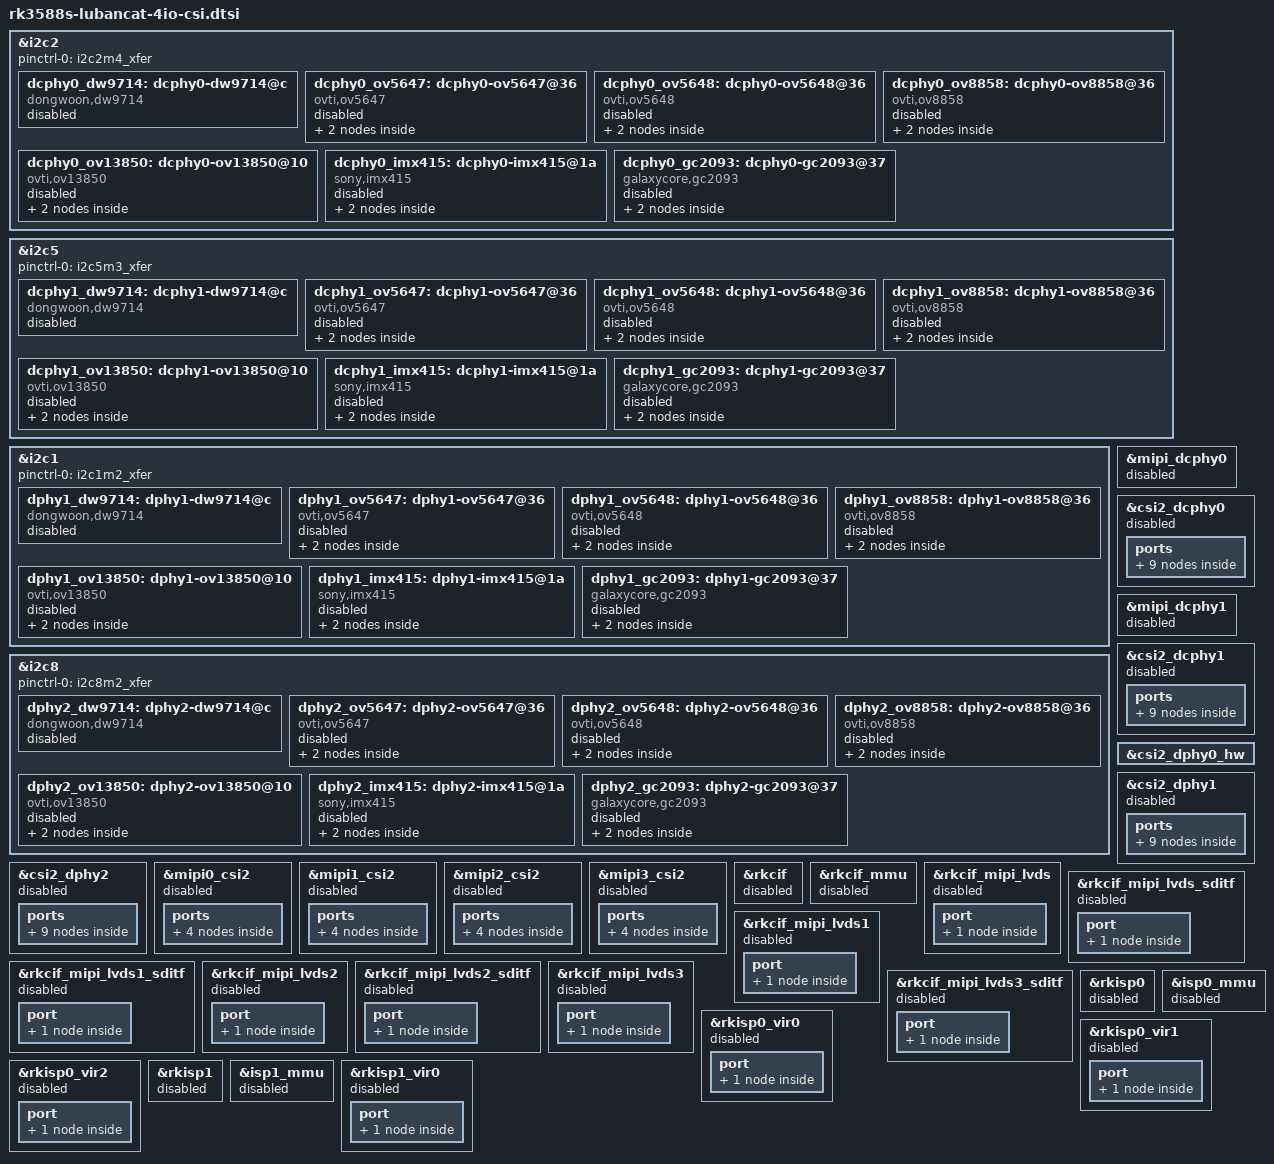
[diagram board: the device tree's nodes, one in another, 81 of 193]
// SPDX-License-Identifier: (GPL-2.0+ OR MIT)
/*
 * Copyright (c) 2020 Rockchip Electronics Co., Ltd.
 *
 */

#include "rk3588-lubancat-cam.dtsi"

/* CAM0 */
&i2c2 {
	status = "okay";
	pinctrl-names = "default";
	pinctrl-0 = <&i2c2m4_xfer>;

	dcphy0_dw9714: dcphy0-dw9714@c {
		status = "disabled";
		compatible = "dongwoon,dw9714";
		reg = <0xc>;
		rockchip,camera-module-index = <0>;
		rockchip,vcm-max-current = <100>;
		rockchip,vcm-start-current = <0>;
		rockchip,vcm-rated-current = <100>;
		rockchip,vcm-step-mode = <0xd>;
		rockchip,vcm-dlc-enable = <0>;
		rockchip,vcm-mclk = <0>;
		rockchip,vcm-t-src = <0>;
		rockchip,camera-module-facing = "back";
	};

	dcphy0_ov5647: dcphy0-ov5647@36 {
		compatible = "ovti,ov5647";
		status = "disabled";
		reg = <0x36>;
		clocks = <&ext_cam_25m_clk>;
		clock-names = "ext_cam_25m_clk";
		pwdn-gpios = <&gpio4 RK_PA6 GPIO_ACTIVE_LOW>;
		lens-focus = <&dcphy0_dw9714>;

		port {
			ov5647_dcphy0_out: endpoint {
				remote-endpoint = <&dcphy0_in_ov5647>;
				data-lanes = <1 2>;
			};
		};
	};

	dcphy0_ov5648: dcphy0-ov5648@36 {
		compatible = "ovti,ov5648";
		status = "disabled";
		reg = <0x36>;
		clocks = <&ext_cam_24m_clk>;
		clock-names = "xvclk";
		dovdd-supply= <&cam_dovdd>; /* 1.8v */
		avdd-supply = <&cam_avdd>;  /* 2.8v */
		dvdd-supply = <&cam_dvdd>;  /* 1.2v */
		pwdn-gpios = <&gpio4 RK_PA6 GPIO_ACTIVE_HIGH>;
		reset-gpios = <&gpio4 RK_PA7 GPIO_ACTIVE_LOW>;
		rotation = <180>;

		rockchip,camera-module-index = <0>;
		rockchip,camera-module-facing = "back";
		rockchip,camera-module-name = "THDS11073";
		rockchip,camera-module-lens-name = "Largan-40122a1";
		lens-focus = <&dcphy0_dw9714>;

		port {
			/* MIPI CSI-2 bus endpoint */
			ov5648_dcphy0_out: endpoint {
				remote-endpoint = <&dcphy0_in_ov5648>;
				clock-lanes = <0>;
				data-lanes = <1 2>;
			};
		};
	};

	dcphy0_ov8858: dcphy0-ov8858@36 {
		compatible = "ovti,ov8858";
		status = "disabled";
		reg = <0x36>;
		clocks = <&ext_cam_24m_clk>;
		clock-names = "xvclk";
		dovdd-supply= <&cam_dovdd>; /* 1.8v */
		avdd-supply = <&cam_avdd>;  /* 2.8v */
		dvdd-supply = <&cam_dvdd>;  /* 1.2v */
		pwdn-gpios = <&gpio4 RK_PA6 GPIO_ACTIVE_HIGH>;
		reset-gpios = <&gpio4 RK_PA7 GPIO_ACTIVE_HIGH>;
		rotation = <180>;

		rockchip,camera-module-index = <0>;
		rockchip,camera-module-facing = "back";
		rockchip,camera-module-name = "HS5885-BNSM1018-V01";
		rockchip,camera-module-lens-name = "default";
		lens-focus = <&dcphy0_dw9714>;

		port {
			/* MIPI CSI-2 bus endpoint */
			ov8858_dcphy0_out: endpoint {
				remote-endpoint = <&dcphy0_in_ov8858>;
				clock-lanes = <0>;
				data-lanes = <1 2>;
			};
		};
	};

   	dcphy0_ov13850: dcphy0-ov13850@10 {
		compatible = "ovti,ov13850";
		status = "disabled";
		reg = <0x10>;
		clocks = <&ext_cam_24m_clk>;
		clock-names = "xvclk";
		dovdd-supply= <&cam_dovdd>; /* 1.8v */
		avdd-supply = <&cam_avdd>;  /* 2.8v */
		dvdd-supply = <&cam_dvdd>;  /* 1.2v */
		pwdn-gpios = <&gpio4 RK_PA6 GPIO_ACTIVE_HIGH>;
		reset-gpios = <&gpio4 RK_PA7 GPIO_ACTIVE_HIGH>;
		rotation = <180>;

		rockchip,camera-module-index = <2>;
		rockchip,camera-module-facing = "back";
		rockchip,camera-module-name = "ZC-OV13850R2A-V1";
		rockchip,camera-module-lens-name = "Largan-50064B31";
		lens-focus = <&dcphy0_dw9714>;

		port {
			/* MIPI CSI-2 bus endpoint */
			ov13850_dcphy0_out: endpoint {
				remote-endpoint = <&dcphy0_in_ov13850>;
				clock-lanes = <0>;
				data-lanes = <1 2>;
			};
		};
	};

	dcphy0_imx415: dcphy0-imx415@1a {
		compatible = "sony,imx415";
		status = "disabled";
		reg = <0x1a>;
		clocks = <&ext_cam_37m_clk>;
		clock-names = "xvclk";
		power-domains = <&power RK3588_PD_VI>;
		avdd-supply = <&cam_avdd>;
		dovdd-supply = <&cam_dovdd>;
		dvdd-supply = <&cam_dvdd>;
		pwdn-gpios = <&gpio4 RK_PA6 GPIO_ACTIVE_HIGH>;
		reset-gpios = <&gpio4 RK_PA7 GPIO_ACTIVE_LOW>;

		rockchip,camera-module-index = <0>;
		rockchip,camera-module-facing = "back";
		rockchip,camera-module-name = "CMK-OT2022-PX1";
		rockchip,camera-module-lens-name = "IR0147-50IRC-8M-F20";
		// NO_HDR:0 HDR_X2:5 HDR_X3:6
		// rockchip,camera-hdr-mode = <0>;
		port {
			imx415_dcphy0_out: endpoint {
				remote-endpoint = <&dcphy0_in_imx415>;
				data-lanes = <1 2 3 4>;
			};
		};
	};

	dcphy0_gc2093: dcphy0-gc2093@37 {
		compatible = "galaxycore,gc2093";
		status = "disabled";
		reg = <0x37>;
		clocks = <&ext_cam_24m_clk>;
		clock-names = "xvclk";
		//power-domains = <&power RK3588_PD_VI>;

		avdd-supply = <&cam_avdd>;
		dovdd-supply = <&cam_dovdd>;
		dvdd-supply = <&cam_dvdd>;
		pwdn-gpios = <&gpio4 RK_PA6 GPIO_ACTIVE_HIGH>;
		reset-gpios = <&gpio4 RK_PA7 GPIO_ACTIVE_LOW>;

		rockchip,camera-module-index = <0>;
		rockchip,camera-module-facing = "front";
		rockchip,camera-module-name = "SIDA209300461";
		rockchip,camera-module-lens-name = "60IRC-F20";

		// NO_HDR:0 HDR_X2:5 HDR_X3:6
		// rockchip,camera-hdr-mode = <0>;
		port {
			gc2093_dcphy0_out: endpoint {
				remote-endpoint = <&dcphy0_in_gc2093>;
				data-lanes = <1 2 3 4>;
			};
		};
	};
};

/* CAM1 */
&i2c5 {
	status = "okay";
	pinctrl-names = "default";
	pinctrl-0 = <&i2c5m3_xfer>;

	dcphy1_dw9714: dcphy1-dw9714@c {
		status = "disabled";
		compatible = "dongwoon,dw9714";
		reg = <0xc>;
		rockchip,camera-module-index = <1>;
		rockchip,vcm-max-current = <100>;
		rockchip,vcm-start-current = <0>;
		rockchip,vcm-rated-current = <100>;
		rockchip,vcm-step-mode = <0xd>;
		rockchip,vcm-dlc-enable = <0>;
		rockchip,vcm-mclk = <0>;
		rockchip,vcm-t-src = <0>;
		rockchip,camera-module-facing = "back";
	};

	dcphy1_ov5647: dcphy1-ov5647@36 {
		compatible = "ovti,ov5647";
		status = "disabled";
		reg = <0x36>;
		clocks = <&ext_cam_25m_clk>;
		clock-names = "ext_cam_25m_clk";
		pwdn-gpios = <&gpio4 RK_PB0 GPIO_ACTIVE_LOW>;
		lens-focus = <&dcphy1_dw9714>;

		port {
			ov5647_dcphy1_out: endpoint {
				remote-endpoint = <&dcphy1_in_ov5647>;
				data-lanes = <1 2>;
			};
		};
	};

	dcphy1_ov5648: dcphy1-ov5648@36 {
		compatible = "ovti,ov5648";
		status = "disabled";
		reg = <0x36>;
		clocks = <&ext_cam_24m_clk>;
		clock-names = "xvclk";
		dovdd-supply= <&cam_dovdd>; /* 1.8v */
		avdd-supply = <&cam_avdd>;  /* 2.8v */
		dvdd-supply = <&cam_dvdd>;  /* 1.2v */
		pwdn-gpios = <&gpio4 RK_PB0 GPIO_ACTIVE_HIGH>;
		reset-gpios = <&gpio4 RK_PA0 GPIO_ACTIVE_LOW>;
		rotation = <180>;

		rockchip,camera-module-index = <1>;
		rockchip,camera-module-facing = "back";
		rockchip,camera-module-name = "THDS11073";
		rockchip,camera-module-lens-name = "Largan-40122a1";
		lens-focus = <&dcphy1_dw9714>;

		port {
			/* MIPI CSI-2 bus endpoint */
			ov5648_dcphy1_out: endpoint {
				remote-endpoint = <&dcphy1_in_ov5648>;
				clock-lanes = <0>;
				data-lanes = <1 2>;
			};
		};
	};

	dcphy1_ov8858: dcphy1-ov8858@36 {
		compatible = "ovti,ov8858";
		status = "disabled";
		reg = <0x36>;
		clocks = <&ext_cam_24m_clk>;
		clock-names = "xvclk";
		dovdd-supply= <&cam_dovdd>; /* 1.8v */
		avdd-supply = <&cam_avdd>;  /* 2.8v */
		dvdd-supply = <&cam_dvdd>;  /* 1.2v */
		pwdn-gpios = <&gpio4 RK_PB0 GPIO_ACTIVE_HIGH>;
		reset-gpios = <&gpio4 RK_PA0 GPIO_ACTIVE_HIGH>;
		rotation = <180>;

		rockchip,camera-module-index = <1>;
		rockchip,camera-module-facing = "back";
		rockchip,camera-module-name = "HS5885-BNSM1018-V01";
		rockchip,camera-module-lens-name = "default";
		lens-focus = <&dcphy1_dw9714>;

		port {
			/* MIPI CSI-2 bus endpoint */
			ov8858_dcphy1_out: endpoint {
				remote-endpoint = <&dcphy1_in_ov8858>;
				clock-lanes = <0>;
				data-lanes = <1 2>;
			};
		};
	};

   dcphy1_ov13850: dcphy1-ov13850@10 {
		compatible = "ovti,ov13850";
		status = "disabled";
		reg = <0x10>;
		clocks = <&ext_cam_24m_clk>;
		clock-names = "xvclk";
		dovdd-supply= <&cam_dovdd>; /* 1.8v */
		avdd-supply = <&cam_avdd>;  /* 2.8v */
		dvdd-supply = <&cam_dvdd>;  /* 1.2v */
		pwdn-gpios = <&gpio4 RK_PB0 GPIO_ACTIVE_HIGH>;
		reset-gpios = <&gpio4 RK_PA0 GPIO_ACTIVE_HIGH>;
		rotation = <180>;

		rockchip,camera-module-index = <1>;
		rockchip,camera-module-facing = "back";
		rockchip,camera-module-name = "ZC-OV13850R2A-V1";
		rockchip,camera-module-lens-name = "Largan-50064B31";
		lens-focus = <&dcphy1_dw9714>;

		port {
			/* MIPI CSI-2 bus endpoint */
			ov13850_dcphy1_out: endpoint {
				remote-endpoint = <&dcphy1_in_ov13850>;
				clock-lanes = <0>;
				data-lanes = <1 2>;
			};
		};
	};

	dcphy1_imx415: dcphy1-imx415@1a {
		compatible = "sony,imx415";
		status = "disabled";
		reg = <0x1a>;
		clocks = <&ext_cam_37m_clk>;
		clock-names = "xvclk";
		power-domains = <&power RK3588_PD_VI>;
		avdd-supply = <&cam_avdd>;
		dovdd-supply = <&cam_dovdd>;
		dvdd-supply = <&cam_dvdd>;
		pwdn-gpios = <&gpio4 RK_PB0 GPIO_ACTIVE_HIGH>;
		reset-gpios = <&gpio4 RK_PA0 GPIO_ACTIVE_LOW>;

		rockchip,camera-module-index = <1>;
		rockchip,camera-module-facing = "back";
		rockchip,camera-module-name = "CMK-OT2022-PX1";
		rockchip,camera-module-lens-name = "IR0147-50IRC-8M-F20";
		port {
			imx415_dcphy1_out: endpoint {
				remote-endpoint = <&dcphy1_in_imx415>;
				data-lanes = <1 2 3 4>;
			};
		};
	};

	dcphy1_gc2093: dcphy1-gc2093@37 {
		compatible = "galaxycore,gc2093";
		status = "disabled";
		reg = <0x37>;
		clocks = <&ext_cam_24m_clk>;
		clock-names = "xvclk";
		//power-domains = <&power RK3588_PD_VI>;

		avdd-supply = <&cam_avdd>;
		dovdd-supply = <&cam_dovdd>;
		dvdd-supply = <&cam_dvdd>;
		pwdn-gpios = <&gpio4 RK_PB0 GPIO_ACTIVE_HIGH>;
		reset-gpios = <&gpio4 RK_PA0 GPIO_ACTIVE_LOW>;

		rockchip,camera-module-index = <0>;
		rockchip,camera-module-facing = "front";
		rockchip,camera-module-name = "SIDA209300461";
		rockchip,camera-module-lens-name = "60IRC-F20";

		// NO_HDR:0 HDR_X2:5 HDR_X3:6
		// rockchip,camera-hdr-mode = <0>;
		port {
			gc2093_dcphy1_out: endpoint {
				remote-endpoint = <&dcphy1_in_gc2093>;
				data-lanes = <1 2 3 4>;
			};
		};
	};
};

/* CAM2 */
&i2c1 {
	status = "okay";
	pinctrl-names = "default";
	pinctrl-0 = <&i2c1m2_xfer>;

	dphy1_dw9714: dphy1-dw9714@c {
		status = "disabled";
		compatible = "dongwoon,dw9714";
		reg = <0xc>;
		rockchip,camera-module-index = <2>;
		rockchip,vcm-max-current = <100>;
		rockchip,vcm-start-current = <0>;
		rockchip,vcm-rated-current = <100>;
		rockchip,vcm-step-mode = <0xd>;
		rockchip,vcm-dlc-enable = <0>;
		rockchip,vcm-mclk = <0>;
		rockchip,vcm-t-src = <0>;
		rockchip,camera-module-facing = "back";
	};

	dphy1_ov5647: dphy1-ov5647@36 {
		compatible = "ovti,ov5647";
		status = "disabled";
		reg = <0x36>;
		clocks = <&ext_cam_25m_clk>;
		clock-names = "ext_cam_25m_clk";
		pwdn-gpios = <&gpio4 RK_PA1 GPIO_ACTIVE_LOW>;
		lens-focus = <&dphy1_dw9714>;

		port {
			ov5647_dphy1_out: endpoint {
				remote-endpoint = <&dphy1_in_ov5647>;
				data-lanes = <1 2>;
			};
		};
	};

	dphy1_ov5648: dphy1-ov5648@36 {
		compatible = "ovti,ov5648";
		status = "disabled";
		reg = <0x36>;
		clocks = <&ext_cam_24m_clk>;
		clock-names = "xvclk";
		dovdd-supply= <&cam_dovdd>; /* 1.8v */
		avdd-supply = <&cam_avdd>;  /* 2.8v */
		dvdd-supply = <&cam_dvdd>;  /* 1.2v */
		pwdn-gpios = <&gpio4 RK_PA1 GPIO_ACTIVE_HIGH>;
		reset-gpios = <&gpio4 RK_PA2 GPIO_ACTIVE_LOW>;
		rotation = <180>;

		rockchip,camera-module-index = <2>;
		rockchip,camera-module-facing = "back";
		rockchip,camera-module-name = "THDS11073";
		rockchip,camera-module-lens-name = "Largan-40122a1";
		lens-focus = <&dphy1_dw9714>;

		port {
			/* MIPI CSI-2 bus endpoint */
			ov5648_dphy1_out: endpoint {
				remote-endpoint = <&dphy1_in_ov5648>;
				clock-lanes = <0>;
				data-lanes = <1 2>;
			};
		};
	};

	dphy1_ov8858: dphy1-ov8858@36 {
		compatible = "ovti,ov8858";
		status = "disabled";
		reg = <0x36>;
		clocks = <&ext_cam_24m_clk>;
		clock-names = "xvclk";
		dovdd-supply= <&cam_dovdd>; /* 1.8v */
		avdd-supply = <&cam_avdd>;  /* 2.8v */
		dvdd-supply = <&cam_dvdd>;  /* 1.2v */
		pwdn-gpios = <&gpio4 RK_PA1 GPIO_ACTIVE_HIGH>;
		reset-gpios = <&gpio4 RK_PA2 GPIO_ACTIVE_HIGH>;
		rotation = <180>;

		rockchip,camera-module-index = <2>;
		rockchip,camera-module-facing = "back";
		rockchip,camera-module-name = "HS5885-BNSM1018-V01";
		rockchip,camera-module-lens-name = "default";
		lens-focus = <&dphy1_dw9714>;

		port {
			/* MIPI CSI-2 bus endpoint */
			ov8858_dphy1_out: endpoint {
				remote-endpoint = <&dphy1_in_ov8858>;
				clock-lanes = <0>;
				data-lanes = <1 2>;
			};
		};
	};

	dphy1_ov13850: dphy1-ov13850@10 {
		compatible = "ovti,ov13850";
		status = "disabled";
		reg = <0x10>;
		clocks = <&ext_cam_24m_clk>;
		clock-names = "xvclk";
		dovdd-supply= <&cam_dovdd>; /* 1.8v */
		avdd-supply = <&cam_avdd>;  /* 2.8v */
		dvdd-supply = <&cam_dvdd>;  /* 1.2v */
		pwdn-gpios = <&gpio4 RK_PA1 GPIO_ACTIVE_HIGH>;
		reset-gpios = <&gpio4 RK_PA2 GPIO_ACTIVE_HIGH>;
		rotation = <180>;

		rockchip,camera-module-index = <2>;
		rockchip,camera-module-facing = "back";
		rockchip,camera-module-name = "ZC-OV13850R2A-V1";
		rockchip,camera-module-lens-name = "Largan-50064B31";
		lens-focus = <&dphy1_dw9714>;

		port {
			/* MIPI CSI-2 bus endpoint */
			ov13850_dphy1_out: endpoint {
				remote-endpoint = <&dphy1_in_ov13850>;
				clock-lanes = <0>;
				data-lanes = <1 2>;
			};
		};
	};

	dphy1_imx415: dphy1-imx415@1a {
		compatible = "sony,imx415";
		status = "disabled";
		reg = <0x1a>;
		clocks = <&ext_cam_37m_clk>;
		clock-names = "xvclk";
		power-domains = <&power RK3588_PD_VI>;
		avdd-supply = <&cam_avdd>;
		dovdd-supply = <&cam_dovdd>;
		dvdd-supply = <&cam_dvdd>;
		pwdn-gpios = <&gpio4 RK_PA1 GPIO_ACTIVE_HIGH>;
		reset-gpios = <&gpio4 RK_PA2 GPIO_ACTIVE_LOW>;

		rockchip,camera-module-index = <0>;
		rockchip,camera-module-facing = "back";
		rockchip,camera-module-name = "CMK-OT2022-PX1";
		rockchip,camera-module-lens-name = "IR0147-50IRC-8M-F20";
		// NO_HDR:0 HDR_X2:5 HDR_X3:6
		// rockchip,camera-hdr-mode = <0>;
		port {
			imx415_dphy1_out: endpoint {
				remote-endpoint = <&dphy1_in_imx415>;
				data-lanes = <1 2>;
			};
		};
	};

	dphy1_gc2093: dphy1-gc2093@37 {
		compatible = "galaxycore,gc2093";
		status = "disabled";
		reg = <0x37>;
		clocks = <&ext_cam_24m_clk>;
		clock-names = "xvclk";
		//power-domains = <&power RK3588_PD_VI>;

		avdd-supply = <&cam_avdd>;
		dovdd-supply = <&cam_dovdd>;
		dvdd-supply = <&cam_dvdd>;
		pwdn-gpios = <&gpio4 RK_PA1 GPIO_ACTIVE_HIGH>;
		reset-gpios = <&gpio4 RK_PA2 GPIO_ACTIVE_LOW>;

		rockchip,camera-module-index = <0>;
		rockchip,camera-module-facing = "front";
		rockchip,camera-module-name = "SIDA209300461";
		rockchip,camera-module-lens-name = "60IRC-F20";

		// NO_HDR:0 HDR_X2:5 HDR_X3:6
		// rockchip,camera-hdr-mode = <0>;
		port {
			gc2093_dphy1_out: endpoint {
				remote-endpoint = <&dphy1_in_gc2093>;
				data-lanes = <1 2>;
			};
		};
	};
};

/* CAM3 */
&i2c8 {
	status = "okay";
	pinctrl-names = "default";
	pinctrl-0 = <&i2c8m2_xfer>;

	dphy2_dw9714: dphy2-dw9714@c {
		status = "disabled";
		compatible = "dongwoon,dw9714";
		reg = <0xc>;
		rockchip,camera-module-index = <0>;
		rockchip,vcm-max-current = <100>;
		rockchip,vcm-start-current = <0>;
		rockchip,vcm-rated-current = <100>;
		rockchip,vcm-step-mode = <0xd>;
		rockchip,vcm-dlc-enable = <0>;
		rockchip,vcm-mclk = <0>;
		rockchip,vcm-t-src = <0>;
		rockchip,camera-module-facing = "back";
	};

	dphy2_ov5647: dphy2-ov5647@36 {
		compatible = "ovti,ov5647";
		status = "disabled";
		reg = <0x36>;
		clocks = <&ext_cam_25m_clk>;
		clock-names = "ext_cam_25m_clk";
		pwdn-gpios = <&gpio4 RK_PB4 GPIO_ACTIVE_LOW>;
		lens-focus = <&dphy2_dw9714>;

		port {
			ov5647_dphy2_out: endpoint {
				remote-endpoint = <&dphy2_in_ov5647>;
				data-lanes = <1 2>;
			};
		};
	};

	dphy2_ov5648: dphy2-ov5648@36 {
		compatible = "ovti,ov5648";
		status = "disabled";
		reg = <0x36>;
		clocks = <&ext_cam_24m_clk>;
		clock-names = "xvclk";
		dovdd-supply= <&cam_dovdd>; /* 1.8v */
		avdd-supply = <&cam_avdd>;  /* 2.8v */
		dvdd-supply = <&cam_dvdd>;  /* 1.2v */
		pwdn-gpios = <&gpio4 RK_PB4 GPIO_ACTIVE_HIGH>;
		reset-gpios = <&gpio4 RK_PB5 GPIO_ACTIVE_LOW>;
		rotation = <180>;

		rockchip,camera-module-index = <2>;
		rockchip,camera-module-facing = "back";
		rockchip,camera-module-name = "THDS11073";
		rockchip,camera-module-lens-name = "Largan-40122a1";
		lens-focus = <&dphy2_dw9714>;

		port {
			/* MIPI CSI-2 bus endpoint */
			ov5648_dphy2_out: endpoint {
				remote-endpoint = <&dphy2_in_ov5648>;
				clock-lanes = <0>;
				data-lanes = <1 2>;
			};
		};
	};

	dphy2_ov8858: dphy2-ov8858@36 {
		compatible = "ovti,ov8858";
		status = "disabled";
		reg = <0x36>;
		clocks = <&ext_cam_24m_clk>;
		clock-names = "xvclk";
		dovdd-supply= <&cam_dovdd>; /* 1.8v */
		avdd-supply = <&cam_avdd>;  /* 2.8v */
		dvdd-supply = <&cam_dvdd>;  /* 1.2v */
		pwdn-gpios = <&gpio4 RK_PB4 GPIO_ACTIVE_HIGH>;
		reset-gpios = <&gpio4 RK_PB5 GPIO_ACTIVE_HIGH>;
		rotation = <180>;

		rockchip,camera-module-index = <2>;
		rockchip,camera-module-facing = "back";
		rockchip,camera-module-name = "HS5885-BNSM1018-V01";
		rockchip,camera-module-lens-name = "default";
		lens-focus = <&dphy2_dw9714>;

		port {
			/* MIPI CSI-2 bus endpoint */
			ov8858_dphy2_out: endpoint {
				remote-endpoint = <&dphy2_in_ov8858>;
				clock-lanes = <0>;
				data-lanes = <1 2>;
			};
		};
	};

	dphy2_ov13850: dphy2-ov13850@10 {
		compatible = "ovti,ov13850";
		status = "disabled";
		reg = <0x10>;
		clocks = <&ext_cam_24m_clk>;
		clock-names = "xvclk";
		dovdd-supply= <&cam_dovdd>; /* 1.8v */
		avdd-supply = <&cam_avdd>;  /* 2.8v */
		dvdd-supply = <&cam_dvdd>;  /* 1.2v */
		pwdn-gpios = <&gpio4 RK_PB4 GPIO_ACTIVE_HIGH>;
		reset-gpios = <&gpio4 RK_PB5 GPIO_ACTIVE_HIGH>;
		rotation = <180>;

		rockchip,camera-module-index = <2>;
		rockchip,camera-module-facing = "back";
		rockchip,camera-module-name = "ZC-OV13850R2A-V1";
		rockchip,camera-module-lens-name = "Largan-50064B31";
		lens-focus = <&dphy2_dw9714>;

		port {
			/* MIPI CSI-2 bus endpoint */
			ov13850_dphy2_out: endpoint {
				remote-endpoint = <&dphy2_in_ov13850>;
				clock-lanes = <0>;
				data-lanes = <1 2>;
			};
		};
	};

	dphy2_imx415: dphy2-imx415@1a {
		compatible = "sony,imx415";
		status = "disabled";
		reg = <0x1a>;
		clocks = <&ext_cam_37m_clk>;
		clock-names = "xvclk";
		power-domains = <&power RK3588_PD_VI>;
		avdd-supply = <&cam_avdd>;
		dovdd-supply = <&cam_dovdd>;
		dvdd-supply = <&cam_dvdd>;
		pwdn-gpios = <&gpio4 RK_PB4 GPIO_ACTIVE_HIGH>;
		reset-gpios = <&gpio4 RK_PB5 GPIO_ACTIVE_LOW>;

		rockchip,camera-module-index = <0>;
		rockchip,camera-module-facing = "back";
		rockchip,camera-module-name = "CMK-OT2022-PX1";
		rockchip,camera-module-lens-name = "IR0147-50IRC-8M-F20";
		// NO_HDR:0 HDR_X2:5 HDR_X3:6
		// rockchip,camera-hdr-mode = <0>;
		port {
			imx415_dphy2_out: endpoint {
				remote-endpoint = <&dphy2_in_imx415>;
				data-lanes = <1 2>;
			};
		};
	};

	dphy2_gc2093: dphy2-gc2093@37 {
		compatible = "galaxycore,gc2093";
		status = "disabled";
		reg = <0x37>;
		clocks = <&ext_cam_24m_clk>;
		clock-names = "xvclk";
		//power-domains = <&power RK3588_PD_VI>;

		avdd-supply = <&cam_avdd>;
		dovdd-supply = <&cam_dovdd>;
		dvdd-supply = <&cam_dvdd>;
		pwdn-gpios = <&gpio4 RK_PB4 GPIO_ACTIVE_HIGH>;
		reset-gpios = <&gpio4 RK_PB5 GPIO_ACTIVE_LOW>;

		rockchip,camera-module-index = <0>;
		rockchip,camera-module-facing = "front";
		rockchip,camera-module-name = "SIDA209300461";
		rockchip,camera-module-lens-name = "60IRC-F20";

		// NO_HDR:0 HDR_X2:5 HDR_X3:6
		// rockchip,camera-hdr-mode = <0>;
		port {
			gc2093_dphy2_out: endpoint {
				remote-endpoint = <&dphy2_in_gc2093>;
				data-lanes = <1 2>;
			};
		};
	};
};


&mipi_dcphy0 {
	status = "disabled";
};

&csi2_dcphy0 {
	status = "disabled";

	ports {
		#address-cells = <1>;
		#size-cells = <0>;

		port@0 {
			reg = <0>;
			#address-cells = <1>;
			#size-cells = <0>;

			dcphy0_in_ov5647: endpoint@0 {
				reg = <0>;
				remote-endpoint = <&ov5647_dcphy0_out>;
				data-lanes = <1 2>;
			};

			dcphy0_in_ov5648: endpoint@1 {
				reg = <1>;
				remote-endpoint = <&ov5648_dcphy0_out>;
				data-lanes = <1 2>;
			};

			dcphy0_in_ov8858: endpoint@2 {
				reg = <2>;
				remote-endpoint = <&ov8858_dcphy0_out>;
				data-lanes = <1 2>;
			};

			dcphy0_in_ov13850: endpoint@3 {
				reg = <3>;
				remote-endpoint = <&ov13850_dcphy0_out>;
				data-lanes = <1 2>;
			};

			dcphy0_in_imx415: endpoint@4 {
				reg = <4>;
				remote-endpoint = <&imx415_dcphy0_out>;
				data-lanes = <1 2 3 4>;
			};

			dcphy0_in_gc2093: endpoint@5 {
				reg = <5>;
				remote-endpoint = <&gc2093_dcphy0_out>;
				data-lanes = <1 2 3 4>;
			};
		};

		port@1 {
			reg = <1>;
			#address-cells = <1>;
			#size-cells = <0>;

			csidcphy0_out: endpoint@0 {
				reg = <0>;
				remote-endpoint = <&mipi0_csi2_input>;
			};
		};
	};
};

&mipi_dcphy1 {
	status = "disabled";
};

&csi2_dcphy1 {
	status = "disabled";

	ports {
		#address-cells = <1>;
		#size-cells = <0>;

		port@0 {
			reg = <0>;
			#address-cells = <1>;
			#size-cells = <0>;

			dcphy1_in_ov5647: endpoint@0 {
				reg = <0>;
				remote-endpoint = <&ov5647_dcphy1_out>;
				data-lanes = <1 2>;
			};

			dcphy1_in_ov5648: endpoint@1 {
				reg = <1>;
				remote-endpoint = <&ov5648_dcphy1_out>;
				data-lanes = <1 2>;
			};

			dcphy1_in_ov8858: endpoint@2 {
				reg = <2>;
				remote-endpoint = <&ov8858_dcphy1_out>;
				data-lanes = <1 2>;
			};

			dcphy1_in_ov13850: endpoint@3 {
				reg = <3>;
				remote-endpoint = <&ov13850_dcphy1_out>;
				data-lanes = <1 2>;
			};

			dcphy1_in_imx415: endpoint@4 {
				reg = <4>;
				remote-endpoint = <&imx415_dcphy1_out>;
				data-lanes = <1 2 3 4>;
			};

			dcphy1_in_gc2093: endpoint@5 {
				reg = <5>;
				remote-endpoint = <&gc2093_dcphy1_out>;
				data-lanes = <1 2 3 4>;
			};
		};

		port@1 {
			reg = <1>;
			#address-cells = <1>;
			#size-cells = <0>;

			csidcphy1_out: endpoint@0 {
				reg = <0>;
				remote-endpoint = <&mipi1_csi2_input>;
			};
		};
	};
};

&csi2_dphy0_hw {
	status = "okay";
};

&csi2_dphy1 {
	status = "disabled";

	ports {
		#address-cells = <1>;
		#size-cells = <0>;

		port@0 {
			reg = <0>;
			#address-cells = <1>;
			#size-cells = <0>;

			dphy1_in_ov5647: endpoint@0 {
				reg = <0>;
				remote-endpoint = <&ov5647_dphy1_out>;
				data-lanes = <1 2>;
			};

			dphy1_in_ov5648: endpoint@1 {
				reg = <1>;
				remote-endpoint = <&ov5648_dphy1_out>;
				data-lanes = <1 2>;
			};

			dphy1_in_ov8858: endpoint@2 {
				reg = <2>;
				remote-endpoint = <&ov8858_dphy1_out>;
				data-lanes = <1 2>;
			};

			dphy1_in_ov13850: endpoint@3 {
				reg = <3>;
				remote-endpoint = <&ov13850_dphy1_out>;
				data-lanes = <1 2>;
			};

			dphy1_in_imx415: endpoint@4 {
				reg = <4>;
				remote-endpoint = <&imx415_dphy1_out>;
				data-lanes = <1 2>;
			};

			dphy1_in_gc2093: endpoint@5 {
				reg = <5>;
				remote-endpoint = <&gc2093_dphy1_out>;
				data-lanes = <1 2>;
			};
		};

		port@1 {
			reg = <1>;
			#address-cells = <1>;
			#size-cells = <0>;

			csidphy1_out: endpoint@0 {
				reg = <0>;
				remote-endpoint = <&mipi2_csi2_input>;
			};
		};
	};
};

&csi2_dphy2 {
	status = "disabled";

	ports {
		#address-cells = <1>;
		#size-cells = <0>;

		port@0 {
			reg = <0>;
			#address-cells = <1>;
			#size-cells = <0>;

			dphy2_in_ov5647: endpoint@0 {
				reg = <0>;
				remote-endpoint = <&ov5647_dphy2_out>;
				data-lanes = <1 2>;
			};

			dphy2_in_ov5648: endpoint@1 {
				reg = <1>;
				remote-endpoint = <&ov5648_dphy2_out>;
				data-lanes = <1 2>;
			};

			dphy2_in_ov8858: endpoint@2 {
				reg = <2>;
				remote-endpoint = <&ov8858_dphy2_out>;
				data-lanes = <1 2>;
			};

			dphy2_in_ov13850: endpoint@3 {
				reg = <3>;
				remote-endpoint = <&ov13850_dphy2_out>;
				data-lanes = <1 2>;
			};

			dphy2_in_imx415: endpoint@4 {
				reg = <4>;
				remote-endpoint = <&imx415_dphy2_out>;
				data-lanes = <1 2>;
			};

			dphy2_in_gc2093: endpoint@5 {
				reg = <5>;
				remote-endpoint = <&gc2093_dphy2_out>;
				data-lanes = <1 2>;
			};
		};

		port@1 {
			reg = <1>;
			#address-cells = <1>;
			#size-cells = <0>;

			csidphy2_out: endpoint@0 {
				reg = <0>;
				remote-endpoint = <&mipi3_csi2_input>;
			};
		};
	};
};

&mipi0_csi2 {
	status = "disabled";

	ports {
		#address-cells = <1>;
		#size-cells = <0>;

		port@0 {
			reg = <0>;
			#address-cells = <1>;
			#size-cells = <0>;

			mipi0_csi2_input: endpoint@1 {
				reg = <1>;
				remote-endpoint = <&csidcphy0_out>;
			};
		};

		port@1 {
			reg = <1>;
			#address-cells = <1>;
			#size-cells = <0>;

			mipi0_csi2_output: endpoint@0 {
				reg = <0>;
				remote-endpoint = <&cif_mipi_in0>;
			};
		};
	};
};

&mipi1_csi2 {
	status = "disabled";

	ports {
		#address-cells = <1>;
		#size-cells = <0>;

		port@0 {
			reg = <0>;
			#address-cells = <1>;
			#size-cells = <0>;

			mipi1_csi2_input: endpoint@1 {
				reg = <1>;
				remote-endpoint = <&csidcphy1_out>;
			};
		};

		port@1 {
			reg = <1>;
			#address-cells = <1>;
			#size-cells = <0>;

			mipi1_csi2_output: endpoint@0 {
				reg = <0>;
				remote-endpoint = <&cif_mipi_in1>;
			};
		};
	};
};

&mipi2_csi2 {
	status = "disabled";

	ports {
		#address-cells = <1>;
		#size-cells = <0>;

		port@0 {
			reg = <0>;
			#address-cells = <1>;
			#size-cells = <0>;

			mipi2_csi2_input: endpoint@1 {
				reg = <1>;
				remote-endpoint = <&csidphy1_out>;
			};
		};

		port@1 {
			reg = <1>;
			#address-cells = <1>;
			#size-cells = <0>;

			mipi2_csi2_output: endpoint@0 {
				reg = <0>;
				remote-endpoint = <&cif_mipi_in2>;
			};
		};
	};
};

&mipi3_csi2 {
	status = "disabled";

	ports {
		#address-cells = <1>;
		#size-cells = <0>;

		port@0 {
			reg = <0>;
			#address-cells = <1>;
			#size-cells = <0>;

			mipi3_csi2_input: endpoint@1 {
				reg = <1>;
				remote-endpoint = <&csidphy2_out>;
			};
		};

		port@1 {
			reg = <1>;
			#address-cells = <1>;
			#size-cells = <0>;

			mipi3_csi2_output: endpoint@0 {
				reg = <0>;
				remote-endpoint = <&cif_mipi0_in3>;
			};
		};
	};
};

&rkcif {
	status = "disabled";
};

&rkcif_mmu {
	status = "disabled";
};

&rkcif_mipi_lvds {
	status = "disabled";

	port {
		cif_mipi_in0: endpoint {
			remote-endpoint = <&mipi0_csi2_output>;
		};
	};
};

&rkcif_mipi_lvds_sditf {
	status = "disabled";

	port {
		mipi_lvds_sditf: endpoint {
			remote-endpoint = <&isp0_vir0>;
		};
	};
};

&rkcif_mipi_lvds1 {
	status = "disabled";

	port {
		cif_mipi_in1: endpoint {
			remote-endpoint = <&mipi1_csi2_output>;
		};
	};
};

&rkcif_mipi_lvds1_sditf {
	status = "disabled";

	port {
		mipi_lvds1_sditf: endpoint {
			remote-endpoint = <&isp0_vir1>;
		};
	};
};

&rkcif_mipi_lvds2 {
	status = "disabled";

	port {
		cif_mipi_in2: endpoint {
			remote-endpoint = <&mipi2_csi2_output>;
		};
	};
};

&rkcif_mipi_lvds2_sditf {
	status = "disabled";

	port {
		mipi_lvds2_sditf: endpoint {
			remote-endpoint = <&isp0_vir2>;
		};
	};
};

&rkcif_mipi_lvds3 {
	status = "disabled";

	port {
		cif_mipi0_in3: endpoint {
			remote-endpoint = <&mipi3_csi2_output>;
		};
	};
};

&rkcif_mipi_lvds3_sditf {
	status = "disabled";

	port {
		mipi_lvds3_sditf: endpoint {
			remote-endpoint = <&isp1_vir0>;
		};
	};
};

&rkisp0 {
	status = "disabled";
};

&isp0_mmu {
	status = "disabled";
};

&rkisp0_vir0 {
	status = "disabled";

	port {
		#address-cells = <1>;
		#size-cells = <0>;

		isp0_vir0: endpoint@0 {
			reg = <0>;
			remote-endpoint = <&mipi_lvds_sditf>;
		};
	};
};

&rkisp0_vir1 {
	status = "disabled";

	port {
		#address-cells = <1>;
		#size-cells = <0>;

		isp0_vir1: endpoint@0 {
			reg = <0>;
			remote-endpoint = <&mipi_lvds1_sditf>;
		};
	};
};

&rkisp0_vir2 {
	status = "disabled";

	port {
		#address-cells = <1>;
		#size-cells = <0>;

		isp0_vir2: endpoint@0 {
			reg = <0>;
			remote-endpoint = <&mipi_lvds2_sditf>;
		};
	};
};

&rkisp1 {
	status = "disabled";
};

&isp1_mmu {
	status = "disabled";
};

&rkisp1_vir0 {
	status = "disabled";

	port {
		#address-cells = <1>;
		#size-cells = <0>;

		isp1_vir0: endpoint@0 {
			reg = <0>;
			remote-endpoint = <&mipi_lvds3_sditf>;
		};
	};
};
